# R7FA6E2BB register map
Vendor: Renesas Electronics Corporation; Series: RA6; File version: 1.30.00
CPU: CM33 r0p4, little endian, MPU, FPU, VTOR, 4 interrupt priority bits, 96 interrupts
Registers are 32-bit, read-write, reset 0x0 unless marked. A register's access mark holds for its fields unless they carry their own. Offsets are from the block's base; [hi:lo] are bit positions; {n}, {i} and the like mark numbered series; 'fields as' and 'values as' point back to an identical list.

## RMPU — Renesas Memory Protection Unit
Base 0x40000000
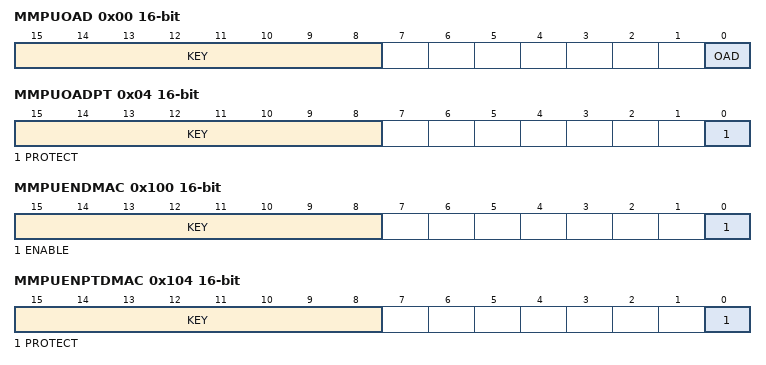
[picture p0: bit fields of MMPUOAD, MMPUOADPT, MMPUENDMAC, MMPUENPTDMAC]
0x00 MMPUOAD 16-bit — MMPU Operation After Detection Register
  [15:8] KEY wo — This bit enables or disables writes to the OAD bit.
  [0] OAD — Operation after detection
0x04 MMPUOADPT 16-bit — MMPU Operation After Detection Protect Register
  [15:8] KEY wo — Key code
  [0] PROTECT — Protection of register
0x100 MMPUENDMAC 16-bit — MMPU Enable Register for DMAC
  [15:8] KEY wo — These bits enable or disable writes to the ENABLE bit.
  [0] ENABLE — Bus Master MPU of DMAC enable
0x104 MMPUENPTDMAC 16-bit — MMPU Enable Protect Register for DMAC
  [15:8] KEY wo — These bits enable or disable writes to the PROTECT bit.
  [0] PROTECT — Protection of register
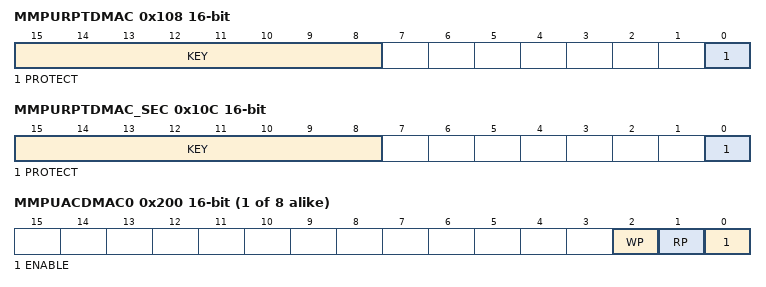
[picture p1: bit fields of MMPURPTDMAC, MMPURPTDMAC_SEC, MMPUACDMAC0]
0x108 MMPURPTDMAC 16-bit — MMPU Regions Protect Register for DMAC
  fields as MMPUENPTDMAC
0x10C MMPURPTDMAC_SEC 16-bit — MMPU Regions Protect register for DMAC Secure
  fields as MMPUENPTDMAC
{0x200+0x10*i} MMPUACDMAC{i} (i=0..7) 16-bit — MMPU Access Control Register for DMAC
  [2] WP — Write protection
  [1] RP — Read protection
  [0] ENABLE — Region enable
{0x204+0x10*i} MMPUSDMAC{i} (i=0..7) (reset mask 0x1F) — MMPU Start Address Register for DMAC
  [31:5] MMPUS — Region start address register
{0x208+0x10*i} MMPUEDMAC{i} (i=0..7) reset 0x1F (reset mask 0x1F) — MMPU End Address Register for DMAC
  [31:5] MMPUE — Region end address register

## TZF — TrustZone Filter
Base 0x40000E00
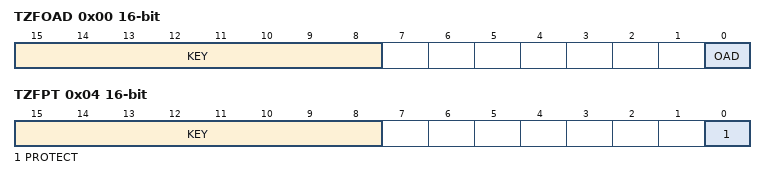
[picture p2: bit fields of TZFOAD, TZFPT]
0x00 TZFOAD 16-bit — TrustZone Filter Operation After Detection Register
  [15:8] KEY wo — KeyCode
  [0] OAD — Operation after detection
0x04 TZFPT 16-bit — TrustZone Filter Protect Register
  [15:8] KEY wo — KeyCode
  [0] PROTECT — Protection of register

## SRAM — SRAM Control
Base 0x40002000
0x00 PARIOAD 8-bit — SRAM Parity Error Operation After Detection Register
  [0] OAD — Operation After Detection
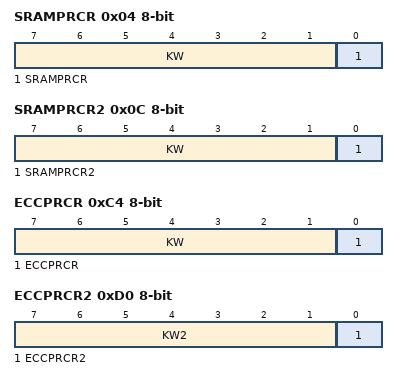
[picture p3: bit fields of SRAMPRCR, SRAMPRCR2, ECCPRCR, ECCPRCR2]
0x04 SRAMPRCR 8-bit — SRAM Protection Register
  [7:1] KW wo — Write Key Code
  [0] SRAMPRCR — Register Write Control
0x08 SRAMWTSC 8-bit reset 0x1 — SRAM Wait State Control Register
  [0] SRAM0WTEN — SRAM0 wait enable
0x0C SRAMPRCR2 8-bit — SRAM Protection Register 2
  [7:1] KW wo — Write Key Code
  [0] SRAMPRCR2 — Register Write Control
0xC0 ECCMODE 8-bit — ECC Operating Mode Control Register
  [1:0] ECCMOD — ECC Operating Mode Select
0xC1 ECC2STS 8-bit — ECC 2-Bit Error Status Register
  [0] ECC2ERR — ECC 2-Bit Error Status
0xC2 ECC1STSEN 8-bit — ECC 1-Bit Error Information Update Enable Register
  [0] E1STSEN — ECC 1-Bit Error Information Update Enable
0xC3 ECC1STS 8-bit — ECC 1-Bit Error Status Register
  [0] ECC1ERR — ECC 1-Bit Error Status
0xC4 ECCPRCR 8-bit — ECC Protection Register
  [7:1] KW wo — Write Key Code
  [0] ECCPRCR — Register Write Control
0xD0 ECCPRCR2 8-bit — ECC Protection Register 2
  [7:1] KW2 wo — Write Key Code
  [0] ECCPRCR2 — Register Write Control
0xD4 ECCETST 8-bit — ECC Test Control Register
  [0] TSTBYP — ECC Bypass Select
0xD8 ECCOAD 8-bit — SRAM ECC Error Operation After Detection Register
  [0] OAD — Operation After Detection

## BUS — Bus Control
Base 0x40003000
0x1100 BUSSCNTFHBIU 16-bit — Slave Bus Control Register
  [1:0] ARBS — Arbitration Select for two masters
0x1104 BUSSCNTFLBIU 16-bit — Slave Bus Control Register
  [1:0] ARBS — Arbitration Select for two masters
0x1110 BUSSCNTS0BIU 16-bit — Slave Bus Control Register
  [1:0] ARBS — Arbitration Select for two masters
0x1120 BUSSCNTPSBIU 16-bit — Slave Bus Control Register
  [0] ARBS — Arbitration Select for two masters
0x1130 BUSSCNTPLBIU 16-bit — Slave Bus Control Register
  [0] ARBS — Arbitration Select for two masters
0x1134 BUSSCNTPHBIU 16-bit — Slave Bus Control Register
  [0] ARBS — Arbitration Select for two masters
0x1140 BUSSCNTEQBIU 16-bit — Slave Bus Control Register
  [1:0] ARBS — Arbitration Select for two masters
{0x17F0+0x10*i} BUS{i}ERRADD (i=1..3) ro — BUS Error Address Register
  [31:0] BERAD — Bus Error Address
{0x17F4+0x10*i} BUS{i}ERRRW (i=1..3) 8-bit — BUS Error Read Write Register
  [0] RWSTAT ro — Error Access Read/Write Status
{0x18F0+0x10*i} BTZF{i}ERRADD (i=1..3) ro — BUS TZF Error Address Register
  [31:0] BTZFERAD — Bus TrustZone Filter Error Address
{0x18F4+0x10*i} BTZF{i}ERRRW (i=1..3) 8-bit — BUS TZF Error Read Write Register
  [0] TRWSTAT ro — TrustZone filter error access Read/Write Status
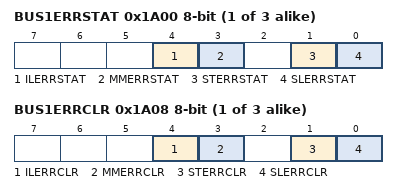
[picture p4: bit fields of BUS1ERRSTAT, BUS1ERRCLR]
{0x19F0+0x10*i} BUS{i}ERRSTAT (i=1..3) 8-bit ro — BUS Error Status Register {i}
  [4] ILERRSTAT — Illegal address access Error Status
  [3] MMERRSTAT — Master MPU Error Status
  [1] STERRSTAT — Slave TrustZone filter Error Status
  [0] SLERRSTAT — Slave bus Error Status
{0x19F8+0x10*i} BUS{i}ERRCLR (i=1..3) 8-bit — BUS Error Clear Register {i}
  [4] ILERRCLR — Illegal Address Access Error Clear
  [3] MMERRCLR — Master MPU Error Clear
  [1] STERRCLR — Slave TrustZone filter Error Clear
  [0] SLERRCLR — Slave bus Error Clear
0x1A24 DMACDTCERRSTAT 8-bit ro — DMAC/DTC Error Status Register
  [0] MTERRSTAT — Master TrustZone Filter Error Status
0x1A2C DMACDTCERRCLR 8-bit — DMAC/DTC Error Clear Register
  [0] MTERRCLR — Master TrustZone filter Error Clear

## Notices in the file
This software is supplied by Renesas Electronics Corporation and is only intended for
use with Renesas products. No other uses are authorized. This software is owned by
Renesas Electronics Corporation and is protected under all applicable laws, including
copyright laws.
THIS SOFTWARE IS PROVIDED "AS IS" AND RENESAS MAKES NO WARRANTIES REGARDING
THIS SOFTWARE, WHETHER EXPRESS, IMPLIED OR STATUTORY, INCLUDING BUT NOT LIMITED TO
WARRANTIES OF MERCHANTABILITY, FITNESS FOR A PARTICULAR PURPOSE AND NON-INFRINGEMENT.
ALL SUCH WARRANTIES ARE EXPRESSLY DISCLAIMED. TO THE MAXIMUM EXTENT PERMITTED NOT
PROHIBITED BY LAW, NEITHER RENESAS ELECTRONICS CORPORATION NOR ANY OF ITS AFFILIATED
COMPANIES SHALL BE LIABLE FOR ANY DIRECT, INDIRECT, SPECIAL, INCIDENTAL OR CONSEQUENTIAL
DAMAGES FOR ANY REASON RELATED TO THIS SOFTWARE, EVEN IF RENESAS OR ITS AFFILIATES HAVE
BEEN ADVISED OF THE POSSIBILITY OF SUCH DAMAGES.
Renesas reserves the right, without notice, to make changes to this software and to
discontinue the availability of this software. By using this software, you agree to
the additional terms and conditions found by accessing the following link:
http://www.renesas.com/disclaimer
